# GAP8 register map
Vendor: GreenWaves Technologies SAS; Series: GAP8; File version: 1.3.1
CPU: other r1p0, little endian, MPU, no FPU, I-cache, DTCM, false interrupt priority bits
Registers are 32-bit, read-write, reset 0x0 unless marked. A register's access mark holds for its fields unless they carry their own. Offsets are from the block's base; [hi:lo] are bit positions; 'fields as' and 'values as' point back to an identical list.

## hwce — Hardware convolution engine
Base 0x10201800
0x00 trigger wo — Trigger the execution of an offloaded job
  [31:0] any — Write of any value will close the current offload phase by releasing the job offload lock and inserting the currently offloaded job in the control queue.
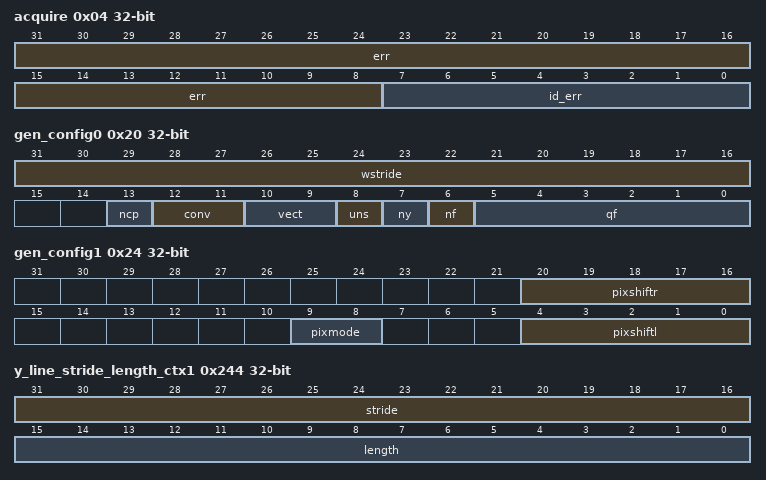
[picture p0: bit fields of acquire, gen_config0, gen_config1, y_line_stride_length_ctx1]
0x04 acquire ro — Acquire the lock to offload job
  [31:8] err — An error code if one of the following conditions apply: 1. if the context copy is going on, it will answer 0xfffffffd (-3) 2. else, if the job offload lock has been established, it will answer 0xfffffffe (-2) 3. else, if the job queue is full, it will answer 0xffffffff (-1)
  [7:0] id_err — If ERR is 0 then the ID of the offloaded job. Otherwise, part of the error code
0x08 finished_jobs ro — Number of concluded jobs since last read
  [31:0] jobs — The number of jobs that the HWCE executed and finished since the last time the same FINISHED_JOBS register was accessed. A read to FINISHED_JOBS returns: - 0x0 if no job was completed since the last access - 0x1 if a single job was completed since the last access - 0x2 if two or more jobs were completed since the last access
0x0C status ro — Status of the HWCE
  [0] st — Status of the HWCE - 1'b0 Not running a job - 1'b1 Running a job
0x10 running_job ro — ID of the currently running job
  [7:0] id
0x14 soft_clear wo — Reset HWCE to known idle state
  [31:0] any — A write of any value to this register will reset the HWCE to its idle state.
0x20 gen_config0 — Generic configuration register 0
  [31:16] wstride — Stride between one FILTER_SIZExFILTER_SIZE filter and the next.
  [13] ncp — No job copy
    0=do_job_copy (set to do job copy); 1=don't_do_job_copy (set to don't do job copy)
  [12:11] conv — Convolution mode
    0=mode_is_5x5 (set to mode is 5x5.); 1=mode_is_3x3 (set to mode is 3x3.); 2=mode_is_4x7 (set to mode is 4x7.)
  [10:9] vect — Vector mode
    0=mode is scalar (1 feat/cycle, 1x16-bit weights); 1=mode is vectorial 2 (2 feat/cycle, 2x8-bit weights); 2=mode is vectorial 4 (4 feat/cycle, 4x4-bit weights)
  [8] uns — Set unsigned multiplication
    0=Consider multiplication results as signed fixed-point numbers; 1=Consider multiplication results as unsigned fixed-point numbers
  [7] ny — No y_in mode
    0=normal_operation (set to Normal operation); 1=Disable loading of y_in and add a constant set in the CONFIG2 register
  [6] nf — Operation type
    0=normal_convolution (set to Normal convolution); 1=Does not flip weights (i.e. implements a stencil instead of a mathematical convolution).
  [5:0] qf — Fixed-point format. Pixels will be shifted to the right by QF bits in the normalization step after the sum-of-products stage.
0x24 gen_config1 — Generic configuration register 1
  [20:16] pixshiftr — Shift output pixels to the right by this number of positions when PIXMODE is not 16bit.
  [9:8] pixmode — Input pixel size - 2'b00 – 16bit - 2'b11 – 16bit bis
    1=8bit (set to 8bit); 2=4bit (set to 4bit)
  [4:0] pixshiftl — Shift input pixels to the left by this number of positions when PIXMODE is not 16bit.
0x40 y_trans_size_aliased — Total number of words to be read for y<sub>in</sub> and y<sub>out</sub>
0x44 y_line_stride_length_aliased — Line stride and length for y<sub>in</sub> and y<sub>out</sub>
0x48 y_feat_stride_length_aliased — Feature (block) stride and length for y<sub>in</sub> and y<sub>out</sub>
0x4C y_out_3_base_addr_aliased — Base address of y<sub>out</sub>[3]
0x50 y_out_2_base_addr_aliased — Base address of y<sub>out</sub>[2]
0x54 y_out_1_base_addr_aliased — Base address of y<sub>out</sub>[1]
0x58 y_out_0_base_addr_aliased — Base address of y<sub>out</sub>[0]
0x5C y_in_3_base_addr_aliased — Base address of y<sub>in</sub>[3]
0x60 y_in_2_base_addr_aliased — Base address of y<sub>in</sub>[2]
0x64 y_in_1_base_addr_aliased — Base address of y<sub>in</sub>[1]
0x68 y_in_0_base_addr_aliased — Base address of y<sub>in</sub>[0]
0x6C x_trans_size_aliased — Total number of words to be read for x<sub>in</sub>
0x70 x_line_stride_length_aliased — Line stride and length for x<sub>in</sub>
0x74 x_feat_stride_length_aliased — Feature (block) stride and length for x<sub>in</sub>
0x78 x_in_base_addr_aliased — Base address of x<sub>in</sub>
0x7C w_base_addr_aliased — Base address of W
0x80 job_config0_aliased — Job configuration register 0
0x84 job_config1_aliased — Job configuration register 1
0x140 y_trans_size_ctx0 ro — Total number of words to be read for y<sub>in</sub> and y<sub>out</sub>
0x144 y_line_stride_length_ctx0 ro — Line stride and length for y<sub>in</sub> and y<sub>out</sub>
0x148 y_feat_stride_length_ctx0 ro — Feature (block) stride and length for y<sub>in</sub> and y<sub>out</sub>
0x14C y_out_3_base_addr_ctx0 ro — Base address of y<sub>out</sub>[3]
0x150 y_out_2_base_addr_ctx0 ro — Base address of y<sub>out</sub>[2]
0x154 y_out_1_base_addr_ctx0 ro — Base address of y<sub>out</sub>[1]
0x158 y_out_0_base_addr_ctx0 ro — Base address of y<sub>out</sub>[0]
0x15C y_in_3_base_addr_ctx0 ro — Base address of y<sub>in</sub>[3]
0x160 y_in_2_base_addr_ctx0 ro — Base address of y<sub>in</sub>[2]
0x164 y_in_1_base_addr_ctx0 ro — Base address of y<sub>in</sub>[1]
0x168 y_in_0_base_addr_ctx0 ro — Base address of y<sub>in</sub>[0]
0x16C x_trans_size_ctx0 ro — Total number of words to be read for x<sub>in</sub>
0x170 x_line_stride_length_ctx0 ro — Line stride and length for x<sub>in</sub>
0x174 x_feat_stride_length_ctx0 ro — Feature (block) stride and length for x<sub>in</sub>
0x178 x_in_base_addr_ctx0 ro — Base address of x<sub>in</sub>
0x17C w_base_addr_ctx0 ro — Base address of W
0x180 job_config0_ctx0 ro — Job configuration register 0
0x184 job_config1_ctx0 ro — Job configuration register 1
0x240 y_trans_size_ctx1 ro — Total number of words to be read for y<sub>in</sub> and y<sub>out</sub>
  [31:0] size — Contains the total number of words (i.e. double 16bit pixels, quad 8bit pixels, etc.) to be read / written by the streaming source and sink interfaces for y<sub>in</sub> and y<sub>out</sub> streams.
0x244 y_line_stride_length_ctx1 ro — Line stride and length for y<sub>in</sub> and y<sub>out</sub>
  [31:16] stride — Distance in bytes between two consecutive lines.
  [15:0] length — Length of a line in number of words
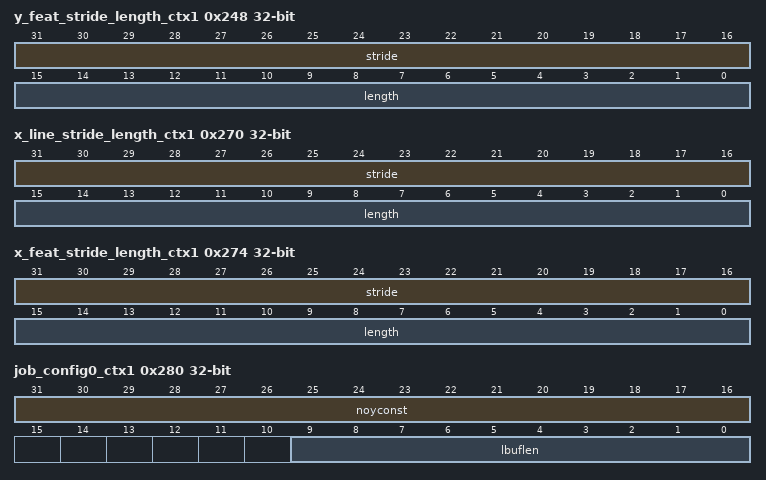
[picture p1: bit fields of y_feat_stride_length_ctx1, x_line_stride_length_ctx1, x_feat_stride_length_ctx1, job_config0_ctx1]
0x248 y_feat_stride_length_ctx1 ro — Feature (block) stride and length for y<sub>in</sub> and y<sub>out</sub>
  fields as y_line_stride_length_ctx1
0x24C y_out_3_base_addr_ctx1 ro — Base address of y<sub>out</sub>[3]
  [31:0] addr — Pointer into cluster L1 memory (4x4 bit mode)
0x250 y_out_2_base_addr_ctx1 ro — Base address of y<sub>out</sub>[2]
  [31:0] addr — Pointer into cluster L1 memory (4x4 bit mode)
0x254 y_out_1_base_addr_ctx1 ro — Base address of y<sub>out</sub>[1]
  [31:0] addr — Pointer into cluster L1 memory (4x4 bit and 2x8 bit modes)
0x258 y_out_0_base_addr_ctx1 ro — Base address of y<sub>out</sub>[0]
  [31:0] addr — Pointer into cluster L1 memory (4x4 bit, 2x8 bit and 1x16 bit modes)
0x25C y_in_3_base_addr_ctx1 ro — Base address of y<sub>in</sub>[3]
  [31:0] addr — Pointer into cluster L1 memory (4x4 bit mode)
0x260 y_in_2_base_addr_ctx1 ro — Base address of y<sub>in</sub>[2]
  [31:0] addr — Pointer into cluster L1 memory (4x4 bit mode)
0x264 y_in_1_base_addr_ctx1 ro — Base address of y<sub>in</sub>[1]
  fields as y_out_1_base_addr_ctx1
0x268 y_in_0_base_addr_ctx1 ro — Base address of y<sub>in</sub>[0]
  fields as y_out_0_base_addr_ctx1
0x26C x_trans_size_ctx1 ro — Total number of words to be read for x<sub>in</sub>
  [31:0] size — Contains the total number of words (i.e. double 16bit pixels, quad 8bit pixels, etc.) to be read / written by the streaming source interface for the x<sub>in</sub> stream.
0x270 x_line_stride_length_ctx1 ro — Line stride and length for x<sub>in</sub>
  fields as y_line_stride_length_ctx1
0x274 x_feat_stride_length_ctx1 ro — Feature (block) stride and length for x<sub>in</sub>
  fields as y_line_stride_length_ctx1
0x278 x_in_base_addr_ctx1 ro — Base address of x<sub>in</sub>
  [31:0] addr — Pointer into cluster L1 memory
0x27C w_base_addr_ctx1 ro — Base address of W
  [31:0] addr — Pointer into cluster L1 memory
0x280 job_config0_ctx1 ro — Job configuration register 0
  [31:16] noyconst — Constant to sum instead of y<sub>in</sub> if the NY flag is active in the CONFIG1 register.
  [9:0] lbuflen — Linebuffer virtual length. Set to the same number as X_LINE_LENGTH. Acceptable LBUFLEN values range between 2 and LINEBUF_LENGTH.
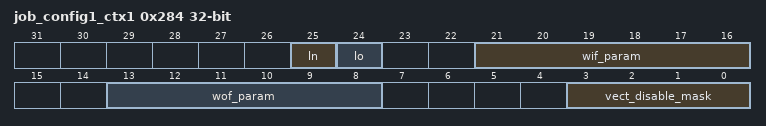
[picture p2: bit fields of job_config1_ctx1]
0x284 job_config1_ctx1 ro — Job configuration register 1
  [25] ln — Looping mechanism
    on read: 0=both counters work as inner loops; 1=outer loop feature address is updated only when the feature counter reaches the wrap parameter, inner loop feature address is updated when the counter is less than the wrap parameter and reset when it is reached
  [24] lo — Loop order
    on read: 0=output features (OF) are the outer loop; 1=input features (IF) are the outer loop
  [21:16] wif_param — Input feature (IF) counter wrap parameter. If both WIF and WOF are 1'b0, the looping mechanism is disabled
  [13:8] wof_param — Output feature (OF) counter wrap parameter. If both WIF and WOF are 1'b0, the looping mechanism is disabled
  [3:0] vect_disable_mask — Vector mode mask. Defaults to 0x0, which means that all vectors are enabled. Can be used to disable unused vector routes when using approximate vector or 3x3 mode. The bits are reversed in order, so bit 3 indicates vector 0, bit 2 vector 1, etc.
